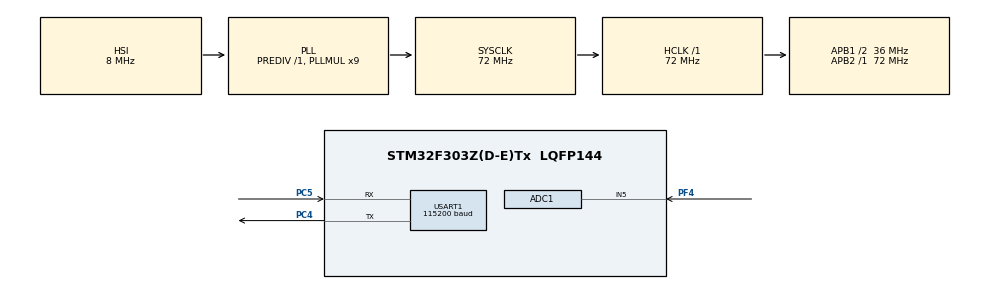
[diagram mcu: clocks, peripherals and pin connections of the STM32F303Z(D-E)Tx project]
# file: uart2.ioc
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ADC1.Channel-0\#ChannelRegularConversion=ADC_CHANNEL_5
ADC1.NbrOfConversionFlag=1
ADC1.Offset-0\#ChannelRegularConversion=0
ADC1.OffsetNumber-0\#ChannelRegularConversion=ADC_OFFSET_NONE
ADC1.Rank-0\#ChannelRegularConversion=1
ADC1.SamplingTime-0\#ChannelRegularConversion=ADC_SAMPLETIME_1CYCLE_5
ADC1.SamplingTimeOPAMP-0\#ChannelRegularConversion=ADC_SAMPLETIME_61CYCLES_5
ADC1.master=1
Mcu.Family=STM32F3
Mcu.Name=STM32F303Z(D-E)Tx
Mcu.Package=LQFP144
NVIC.PriorityGroup=NVIC_PRIORITYGROUP_4
PC4.Mode=Asynchronous
PC4.Signal=USART1_TX
PC5.Mode=Asynchronous
PC5.Signal=USART1_RX
PF4.Mode=IN5-Single-Ended
PF4.Signal=ADC1_IN5
ProjectManager.HeapSize=0x200
ProjectManager.StackSize=0x400
ProjectManager.TargetToolchain=STM32CubeIDE
RCC.AHBFreq_Value=72000000
RCC.APB1CLKDivider=RCC_HCLK_DIV2
RCC.APB1Freq_Value=36000000
RCC.APB1TimFreq_Value=72000000
RCC.APB2Freq_Value=72000000
RCC.APB2TimFreq_Value=72000000
RCC.CortexFreq_Value=72000000
RCC.HCLKFreq_Value=72000000
RCC.HSE_VALUE=8000000
RCC.HSI_VALUE=8000000
RCC.PLLMUL=RCC_PLL_MUL9
RCC.PRESCALERUSB=RCC_USBCLKSOURCE_PLL_DIV1_5
RCC.SYSCLKFreq_VALUE=72000000
RCC.SYSCLKSourceVirtual=RCC_SYSCLKSOURCE_PLLCLK
RCC.USBFreq_Value=48000000
USART1.BaudRate=115200
USART1.VirtualMode-Asynchronous=VM_ASYNC
VP_RTC_VS_RTC_Activate.Mode=RTC_Enabled
board=NUCLEO-F303ZE

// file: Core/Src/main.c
/* USER CODE BEGIN Header */
/**
  ******************************************************************************
  * @file           : main.c
  * @brief          : Main program body
  ******************************************************************************
  * @attention
  *
  * Copyright (c) 2025 STMicroelectronics.
  * All rights reserved.
  *
  * This software is licensed under terms that can be found in the LICENSE file
  * in the root directory of this software component.
  * If no LICENSE file comes with this software, it is provided AS-IS.
  *
  ******************************************************************************
  */
/* USER CODE END Header */
#include "main.h"
#include <stdio.h>
#include <string.h>

/* USER CODE BEGIN PD */
#define COEFF_B0 (1.0f / 18.0f)
#define COEFF_B1 (1.0f / 18.0f)
#define COEFF_A1 (8.0f / 9.0f)

/* USER CODE END PD */

ADC_HandleTypeDef hadc1;

RTC_HandleTypeDef hrtc;

UART_HandleTypeDef huart1;

/* USER CODE BEGIN PV */
static float prev_input = 0.0f;
static float prev_output = 0.0f;

/* USER CODE END PV */

void SystemClock_Config(void);
static void MX_GPIO_Init(void);
static void MX_RTC_Init(void);
static void MX_ADC1_Init(void);
static void MX_USART1_UART_Init(void);

int main(void)
{

  /* MCU Configuration--------------------------------------------------------*/

  /* Reset of all peripherals, Initializes the Flash interface and the Systick. */
  HAL_Init();

  /* Configure the system clock */
  SystemClock_Config();

  /* Initialize all configured peripherals */
  MX_GPIO_Init();
  MX_RTC_Init();
  MX_ADC1_Init();
  MX_USART1_UART_Init();
  /* USER CODE BEGIN 2 */
  char msg[30];// Buffer to store message
  uint16_t adc_val = 0; // Raw ADC value variable
  uint16_t filtered_val_tx = 0; // Filtered value to be transmitted
  float current_filtered_val = 0.0f; // ADC value variable

  /* USER CODE END 2 */

  /* Infinite loop */
  /* USER CODE BEGIN WHILE */
  while (1)
  {
        /* NOTE: For a precise 1700 Hz sampling rate, a hardware timer should be used
         * to trigger the ADC conversion. Polling in a while-loop as done here will
         * result in timing
         */
  HAL_ADC_Start(&hadc1);
  HAL_ADC_PollForConversion(&hadc1, HAL_MAX_DELAY);
  adc_val = HAL_ADC_GetValue(&hadc1);
  HAL_ADC_Stop(&hadc1);

        /* Apply the IIR low-pass filter */
  current_filtered_val = (COEFF_B0 * adc_val) + (COEFF_B1 * prev_input) + (COEFF_A1 * prev_output);

        /* Update state variables for the next iteration */
  prev_input = (float)adc_val;
  prev_output = current_filtered_val;

        /* Prepare the filtered value for transmission */
  filtered_val_tx = (uint16_t)current_filtered_val;

  sprintf(msg, "%d\r\n", filtered_val_tx); // Format filtered data
  HAL_UART_Transmit(&huart1, (uint8_t*)msg, strlen(msg), HAL_MAX_DELAY);

  }

  /* USER CODE END 3 */
}

void SystemClock_Config(void)
{
  RCC_OscInitTypeDef RCC_OscInitStruct = {0};
  RCC_ClkInitTypeDef RCC_ClkInitStruct = {0};
  RCC_PeriphCLKInitTypeDef PeriphClkInit = {0};

  /** Initializes the RCC Oscillators according to the specified parameters
  * in the RCC_OscInitTypeDef structure.
  */
  RCC_OscInitStruct.OscillatorType = RCC_OSCILLATORTYPE_HSI|RCC_OSCILLATORTYPE_LSI;
  RCC_OscInitStruct.HSIState = RCC_HSI_ON;
  RCC_OscInitStruct.HSICalibrationValue = RCC_HSICALIBRATION_DEFAULT;
  RCC_OscInitStruct.LSIState = RCC_LSI_ON;
  RCC_OscInitStruct.PLL.PLLState = RCC_PLL_ON;
  RCC_OscInitStruct.PLL.PLLSource = RCC_PLLSOURCE_HSI;
  RCC_OscInitStruct.PLL.PLLMUL = RCC_PLL_MUL9;
  RCC_OscInitStruct.PLL.PREDIV = RCC_PREDIV_DIV1;
  if (HAL_RCC_OscConfig(&RCC_OscInitStruct) != HAL_OK)
  {
    Error_Handler();
  }

  /** Initializes the CPU, AHB and APB buses clocks
  */
  RCC_ClkInitStruct.ClockType = RCC_CLOCKTYPE_HCLK|RCC_CLOCKTYPE_SYSCLK
                              |RCC_CLOCKTYPE_PCLK1|RCC_CLOCKTYPE_PCLK2;
  RCC_ClkInitStruct.SYSCLKSource = RCC_SYSCLKSOURCE_PLLCLK;
  RCC_ClkInitStruct.AHBCLKDivider = RCC_SYSCLK_DIV1;
  RCC_ClkInitStruct.APB1CLKDivider = RCC_HCLK_DIV2;
  RCC_ClkInitStruct.APB2CLKDivider = RCC_HCLK_DIV1;

  if (HAL_RCC_ClockConfig(&RCC_ClkInitStruct, FLASH_LATENCY_2) != HAL_OK)
  {
    Error_Handler();
  }
  PeriphClkInit.PeriphClockSelection = RCC_PERIPHCLK_USART1|RCC_PERIPHCLK_RTC
                              |RCC_PERIPHCLK_ADC12;
  PeriphClkInit.Usart1ClockSelection = RCC_USART1CLKSOURCE_PCLK2;
  PeriphClkInit.Adc12ClockSelection = RCC_ADC12PLLCLK_DIV1;
  PeriphClkInit.RTCClockSelection = RCC_RTCCLKSOURCE_LSI;
  if (HAL_RCCEx_PeriphCLKConfig(&PeriphClkInit) != HAL_OK)
  {
    Error_Handler();
  }
}

static void MX_ADC1_Init(void)
{

  ADC_MultiModeTypeDef multimode = {0};
  ADC_ChannelConfTypeDef sConfig = {0};

  /** Common config
  */
  hadc1.Instance = ADC1;
  hadc1.Init.ClockPrescaler = ADC_CLOCK_ASYNC_DIV1;
  hadc1.Init.Resolution = ADC_RESOLUTION_12B;
  hadc1.Init.ScanConvMode = ADC_SCAN_DISABLE;
  hadc1.Init.ContinuousConvMode = DISABLE;
  hadc1.Init.DiscontinuousConvMode = DISABLE;
  hadc1.Init.ExternalTrigConvEdge = ADC_EXTERNALTRIGCONVEDGE_NONE;
  hadc1.Init.ExternalTrigConv = ADC_SOFTWARE_START;
  hadc1.Init.DataAlign = ADC_DATAALIGN_RIGHT;
  hadc1.Init.NbrOfConversion = 1;
  hadc1.Init.DMAContinuousRequests = DISABLE;
  hadc1.Init.EOCSelection = ADC_EOC_SINGLE_CONV;
  hadc1.Init.LowPowerAutoWait = DISABLE;
  hadc1.Init.Overrun = ADC_OVR_DATA_OVERWRITTEN;
  if (HAL_ADC_Init(&hadc1) != HAL_OK)
  {
    Error_Handler();
  }

  /** Configure the ADC multi-mode
  */
  multimode.Mode = ADC_MODE_INDEPENDENT;
  if (HAL_ADCEx_MultiModeConfigChannel(&hadc1, &multimode) != HAL_OK)
  {
    Error_Handler();
  }

  /** Configure Regular Channel
  */
  sConfig.Channel = ADC_CHANNEL_5;
  sConfig.Rank = ADC_REGULAR_RANK_1;
  sConfig.SingleDiff = ADC_SINGLE_ENDED;
  sConfig.SamplingTime = ADC_SAMPLETIME_1CYCLE_5;
  sConfig.OffsetNumber = ADC_OFFSET_NONE;
  sConfig.Offset = 0;
  if (HAL_ADC_ConfigChannel(&hadc1, &sConfig) != HAL_OK)
  {
    Error_Handler();
  }

}

static void MX_RTC_Init(void)
{

  /** Initialize RTC Only
  */
  hrtc.Instance = RTC;
  hrtc.Init.HourFormat = RTC_HOURFORMAT_24;
  hrtc.Init.AsynchPrediv = 127;
  hrtc.Init.SynchPrediv = 255;
  hrtc.Init.OutPut = RTC_OUTPUT_DISABLE;
  hrtc.Init.OutPutPolarity = RTC_OUTPUT_POLARITY_HIGH;
  hrtc.Init.OutPutType = RTC_OUTPUT_TYPE_OPENDRAIN;
  if (HAL_RTC_Init(&hrtc) != HAL_OK)
  {
    Error_Handler();
  }

}

static void MX_USART1_UART_Init(void)
{

  huart1.Instance = USART1;
  huart1.Init.BaudRate = 115200;
  huart1.Init.WordLength = UART_WORDLENGTH_8B;
  huart1.Init.StopBits = UART_STOPBITS_1;
  huart1.Init.Parity = UART_PARITY_NONE;
  huart1.Init.Mode = UART_MODE_TX_RX;
  huart1.Init.HwFlowCtl = UART_HWCONTROL_NONE;
  huart1.Init.OverSampling = UART_OVERSAMPLING_16;
  huart1.Init.OneBitSampling = UART_ONE_BIT_SAMPLE_DISABLE;
  huart1.AdvancedInit.AdvFeatureInit = UART_ADVFEATURE_NO_INIT;
  if (HAL_UART_Init(&huart1) != HAL_OK)
  {
    Error_Handler();
  }

}

static void MX_GPIO_Init(void)
{

  /* GPIO Ports Clock Enable */
  __HAL_RCC_GPIOF_CLK_ENABLE();
  __HAL_RCC_GPIOC_CLK_ENABLE();

}

void Error_Handler(void)
{
  __disable_irq();
  while (1)
  {
  }
}
